# STM32F745 register map
File version: 1.6
CPU: CM7 r0p1, little endian, MPU, FPU, 4 interrupt priority bits
Registers are 32-bit, read-write, reset 0x0 unless marked. A register's access mark holds for its fields unless they carry their own. Offsets are from the block's base; [hi:lo] are bit positions; 'fields as' and 'values as' point back to an identical list.

## Ethernet_MAC — Ethernet: media access control (MAC)
Base 0x40028000
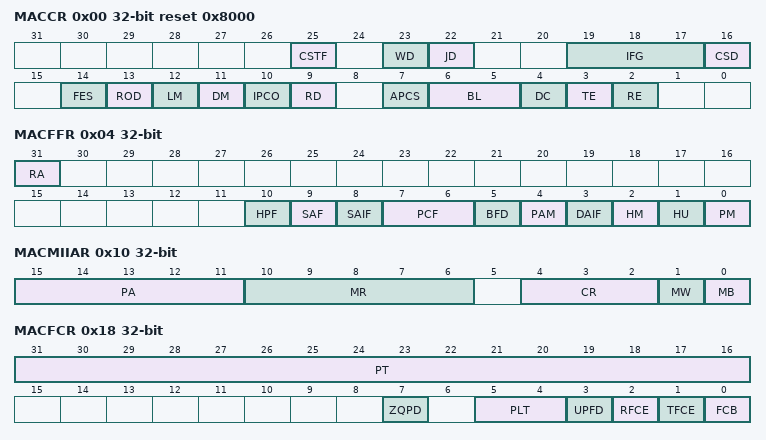
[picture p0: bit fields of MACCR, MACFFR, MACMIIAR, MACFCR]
0x00 MACCR reset 0x8000 — Ethernet MAC configuration register
  [25] CSTF — CRC stripping for type frames
    0=Disabled (CRC not stripped); 1=Enabled (CRC stripped)
  [23] WD — Watchdog disable
    0=Enabled (Watchdog enabled, receive frames limited to 2048 bytes); 1=Disabled (Watchdog disabled, receive frames may be up to to 16384 bytes)
  [22] JD — Jabber disable
    0=Enabled (Jabber enabled, transmit frames up to 2048 bytes); 1=Disabled (Jabber disabled, transmit frames up to 16384 bytes)
  [19:17] IFG — Interframe gap
    0=96 bit times; 1=88 bit times; 2=80 bit times; 3=72 bit times; 4=64 bit times; 5=56 bit times; 6=48 bit times; 7=40 bit times
  [16] CSD — Carrier sense disable
    0=Enabled (Errors generated due to loss of carrier); 1=Disabled (No error generated due to loss of carrier)
  [14] FES — Fast Ethernet speed
    0=10 Mbit/s; 1=100 Mbit/s
  [13] ROD — Receive own disable
    0=Enabled (MAC receives all packets from PHY while transmitting); 1=Disabled (MAC disables reception of frames in half-duplex mode)
  [12] LM — Loopback mode
    0=Normal mode; 1=Loopback (MAC operates in loopback mode at the MII)
  [11] DM — Duplex mode
    0=HalfDuplex (MAC operates in half-duplex mode); 1=FullDuplex (MAC operates in full-duplex mode)
  [10] IPCO — IPv4 checksum offload
    0=Disabled (IPv4 checksum offload disabled); 1=Offload (IPv4 checksums are checked in received frames)
  [9] RD — Retry disable
    0=Enabled (MAC attempts retries based on the settings of BL); 1=Disabled (MAC attempts only 1 transmission)
  [7] APCS — Automatic pad/CRC stripping
    0=Disabled (MAC passes all incoming frames unmodified); 1=Strip (MAC strips the Pad/FCS field on incoming frames only for lengths less than or equal to 1500 bytes)
  [6:5] BL — Back-off limit
    0=For retransmission n, wait up to 2^min(n, 10) time slots; 1=For retransmission n, wait up to 2^min(n, 8) time slots; 2=For retransmission n, wait up to 2^min(n, 4) time slots; 3=For retransmission n, wait up to 2^min(n, 1) time slots
  [4] DC — Deferral check
    0=Disabled (MAC defers until CRS signal goes inactive); 1=Enabled (Deferral check function enabled)
  [3] TE — Transmitter enable
    0=Disabled (MAC transmit state machine is disabled after completion of the transmission of the current frame); 1=Enabled (MAC transmit state machine is enabled)
  [2] RE — Receiver enable
    0=Disabled (MAC receive state machine is disabled after the completion of the reception of the current frame); 1=Enabled (MAC receive state machine is enabled)
0x04 MACFFR — Ethernet MAC frame filter register
  [31] RA — Receive all
    0=Disabled (MAC receiver passes on to the application only those frames that have passed the SA/DA address file); 1=Enabled (MAC receiver passes oll received frames on to the application)
  [10] HPF — Hash or perfect filter
    0=HashOnly (If HM or HU is set, only frames that match the Hash filter are passed); 1=HashOrPerfect (If HM or HU is set, frames that match either the perfect filter or the hash filter are passed)
  [9] SAF — Source address filter
    0=Disabled (Source address ignored); 1=Enabled (MAC drops frames that fail the source address filter)
  [8] SAIF — Source address inverse filtering
    0=Normal (Source address filter operates normally); 1=Invert (Source address filter operation inverted)
  [7:6] PCF — Pass control frames
    0=PreventAll (MAC prevents all control frames from reaching the application); 1=ForwardAllExceptPause (MAC forwards all control frames to application except Pause); 2=ForwardAll (MAC forwards all control frames to application even if they fail the address filter); 3=ForwardAllFiltered (MAC forwards control frames that pass the address filter)
  [5] BFD — Broadcast frames disable
    0=Enabled (Address filters pass all received broadcast frames); 1=Disabled (Address filters filter all incoming broadcast frames)
  [4] PAM — Pass all multicast
    0=Disabled (Filtering of multicast frames depends on HM); 1=Enabled (All received frames with a multicast destination address are passed)
  [3] DAIF — Destination address unique filtering
    0=Normal filtering of frames; 1=Invert (Address check block operates in inverse filtering mode for the DA address comparison)
  [2] HM — Hash multicast
    0=Perfect (MAC performs a perfect destination address filtering for multicast frames); 1=Hash (MAC performs destination address filtering of received multicast frames according to the hash table)
  [1] HU — Hash unicast
    0=Perfect (MAC performs a perfect destination address filtering for unicast frames); 1=Hash (MAC performs destination address filtering of received unicast frames according to the hash table)
  [0] PM — Promiscuous mode
    0=Disabled (Normal address filtering); 1=Enabled (Address filters pass all incoming frames regardless of their destination or source address)
0x08 MACHTHR — Ethernet MAC hash table high register
  [31:0] HTH — Upper 32 bits of hash table
0x0C MACHTLR — Ethernet MAC hash table low register
  [31:0] HTL — Lower 32 bits of hash table
0x10 MACMIIAR — Ethernet MAC MII address register
  [15:11] PA — PHY address - select which of possible 32 PHYs is being accessed
  [10:6] MR — MII register - select the desired MII register in the PHY device
  [4:2] CR — Clock range
    0=CR_60_100 (60-100MHz HCLK/42); 1=CR_100_150 (100-150 MHz HCLK/62); 2=CR_20_35 (20-35MHz HCLK/16); 3=CR_35_60 (35-60MHz HCLK/16); 4=CR_150_168 (150-168MHz HCLK/102)
  [1] MW — MII write
    0=Read operation; 1=Write operation
  [0] MB — MII busy
    1=Busy (This bit is set to 1 by the application to indicate that a read or write access is in progress)
0x14 MACMIIDR — Ethernet MAC MII data register
  [15:0] MD — MII data read from/written to the PHY
0x18 MACFCR — Ethernet MAC flow control register
  [31:16] PT — Pause time
  [7] ZQPD — Zero-quanta pause disable
    0=Enabled (Normal operation with automatic zero-quanta pause control frame generation); 1=Disabled (Automatic generation of zero-quanta pause control frames is disabled)
  [5:4] PLT — Pause low threshold
    0=Pause time minus 4 slot times; 1=Pause time minus 28 slot times; 2=Pause time minus 144 slot times; 3=Pause time minus 256 slot times
  [3] UPFD — Unicast pause frame detect
    0=Disabled (MAC detects only a Pause frame with the multicast address specified in the 802.3x standard); 1=Enabled (MAC additionally detects Pause frames with the station's unicast address)
  [2] RFCE — Receive flow control enable
    0=Disabled (Pause frames are not decoded); 1=Enabled (MAC decodes received Pause frames and disables its transmitted for a specified time)
  [1] TFCE — Transmit flow control enable
    0=Disabled (In full duplex, flow control is disabled. In half duplex, back pressure is disabled); 1=Enabled (In full duplex, flow control is enabled. In half duplex, back pressure is enabled)
  [0] FCB — Flow control busy/back pressure activate
    0=DisableBackPressure (In half duplex only, deasserts back pressure); 1=PauseOrBackPressure (In full duplex, initiate a Pause control frame. In half duplex, assert back pressure)
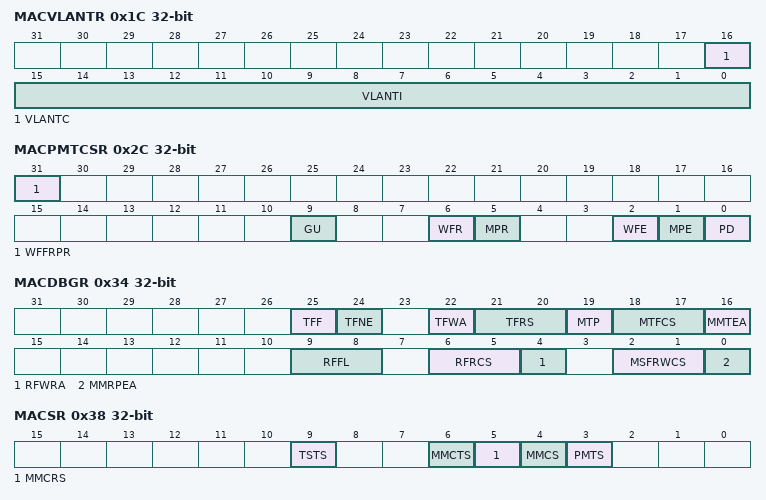
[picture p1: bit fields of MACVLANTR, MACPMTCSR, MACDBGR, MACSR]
0x1C MACVLANTR — Ethernet MAC VLAN tag register
  [16] VLANTC — 12-bit VLAN tag comparison
    0=Full 16 bit VLAN identifiers are used for comparison and filtering; 1=12 bit VLAN identifies are used for comparison and filtering
  [15:0] VLANTI — VLAN tag identifier (for receive frames)
0x2C MACPMTCSR — Ethernet MAC PMT control and status register
  [31] WFFRPR — Wakeup frame filter register pointer reset
    1=Reset wakeup frame filter register point to 0b000. Automatically cleared
  [9] GU — Global unicast
    0=Disabled (Normal operation); 1=Enabled (Any unicast packet filtered by the MAC address recognition may be a wakeup frame)
  [6] WFR — Wakeup frame received
  [5] MPR — Magic packet received
  [2] WFE — Wakeup frame enable
    0=Disabled (No power management event generated due to wakeup frame reception); 1=Enabled (Enable generation of a power management event due to wakeup frame reception)
  [1] MPE — Magic packet enable
    0=Disabled (No power management event generated due to Magic Packet reception); 1=Enabled (Enable generation of a power management event due to Magic Packet reception)
  [0] PD — Power down
    1=Enabled (All received frames will be dropped. Cleared automatically when a magic packet or wakeup frame is received)
0x34 MACDBGR ro — Ethernet MAC debug register
  [25] TFF — Tx FIFO full
  [24] TFNE — Tx FIFO not empty
  [22] TFWA — Tx FIFO write active
  [21:20] TFRS — Tx FIFO read status
  [19] MTP — MAC transmitter in pause
  [18:17] MTFCS — MAC transmit frame controller status
  [16] MMTEA — MAC MII transmit engine active
  [9:8] RFFL — Rx FIFO fill level
  [6:5] RFRCS — Rx FIFO read controller status
  [4] RFWRA — Rx FIFO write controller active
  [2:1] MSFRWCS — MAC small FIFO read/write controllers status
  [0] MMRPEA — MAC MII receive protocol engine active
0x38 MACSR access per field — Ethernet MAC interrupt status register
  [9] TSTS rw — Time stamp trigger status
  [6] MMCTS ro — MMC transmit status
  [5] MMCRS ro — MMC receive status
  [4] MMCS ro — MMC status
  [3] PMTS ro — PMT status
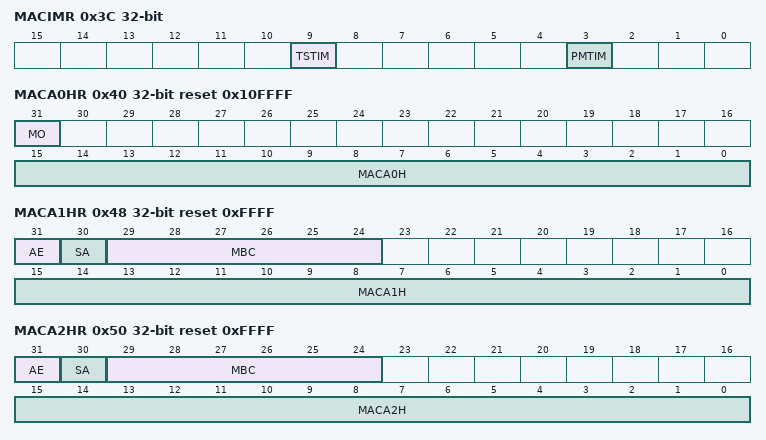
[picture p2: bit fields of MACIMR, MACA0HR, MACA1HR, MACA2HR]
0x3C MACIMR — Ethernet MAC interrupt mask register
  [9] TSTIM — Time stamp trigger interrupt mask
    0=Unmasked (Time stamp interrupt generation enabled); 1=Masked (Time stamp interrupt generation disabled)
  [3] PMTIM — PMT interrupt mask
    0=Unmasked (PMT Status interrupt generation enabled); 1=Masked (PMT Status interrupt generation disabled)
0x40 MACA0HR access per field reset 0x10FFFF — Ethernet MAC address 0 high register
  [31] MO ro — Always 1
  [15:0] MACA0H rw — MAC address0 high
0x44 MACA0LR reset 0xFFFFFFFF — Ethernet MAC address 0 low register
  [31:0] MACA0L — 0
0x48 MACA1HR reset 0xFFFF — Ethernet MAC address 1 high register
  [31] AE
    0=Disabled (Address filters ignore this address); 1=Enabled (Address filters use this address)
  [30] SA
    0=Destination (This address is used for comparison with DA fields of the received frame); 1=Source (This address is used for comparison with SA fields of received frames)
  [29:24] MBC
  [15:0] MACA1H
0x4C MACA1LR reset 0xFFFFFFFF — Ethernet MAC address1 low register
  [31:0] MACA1L — MACA1LR
0x50 MACA2HR reset 0xFFFF — Ethernet MAC address 2 high register
  [31] AE
    values as MACA1HR.AE
  [30] SA
    values as MACA1HR.SA
  [29:24] MBC
  [15:0] MACA2H — MAC2AH
0x54 MACA2LR reset 0xFFFFFFFF — Ethernet MAC address 2 low register
  [31:0] MACA2L
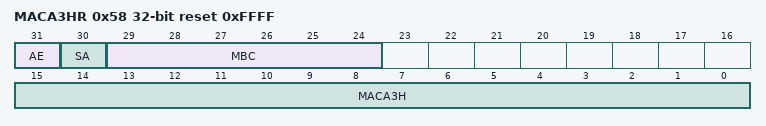
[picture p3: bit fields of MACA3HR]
0x58 MACA3HR reset 0xFFFF — Ethernet MAC address 3 high register
  [31] AE
    values as MACA1HR.AE
  [30] SA
    values as MACA1HR.SA
  [29:24] MBC
  [15:0] MACA3H
0x5C MACA3LR reset 0xFFFFFFFF — Ethernet MAC address 3 low register
  [31:0] MACA3L — MBCA3L
0x60 MACRWUFFER reset 0xFFFFFFFF — Ethernet MAC remote wakeup frame filter register
